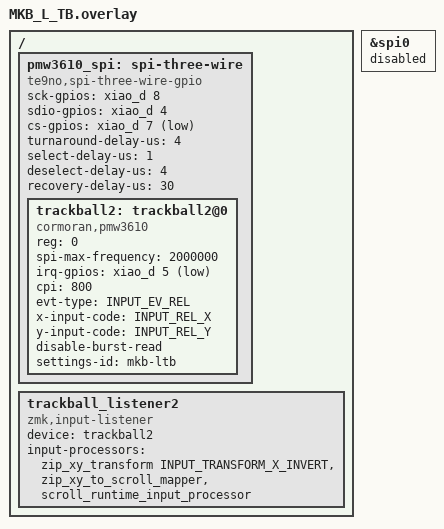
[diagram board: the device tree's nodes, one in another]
/ {
	pmw3610_spi: spi-three-wire {
		compatible = "te9no,spi-three-wire-gpio";
		status = "okay";
		#address-cells = <1>;
		#size-cells = <0>;

		/* MKB left TB wiring: SCK=P1.13 (D8), shared SDIO=P0.04 (D4). */
		sck-gpios = <&xiao_d 8 GPIO_ACTIVE_HIGH>;
		sdio-gpios = <&xiao_d 4 GPIO_ACTIVE_HIGH>;
		cs-gpios = <&xiao_d 7 GPIO_ACTIVE_LOW>;

		turnaround-delay-us = <4>;
		select-delay-us = <1>;
		deselect-delay-us = <4>;
		recovery-delay-us = <30>;

		trackball2: trackball2@0 {
			status = "okay";
			compatible = "cormoran,pmw3610";
			reg = <0>;
			spi-max-frequency = <2000000>;
			irq-gpios = <&xiao_d 5 (GPIO_ACTIVE_LOW | GPIO_PULL_UP)>;
			cpi = <800>;
			evt-type = <INPUT_EV_REL>;
			x-input-code = <INPUT_REL_X>;
			y-input-code = <INPUT_REL_Y>;
			disable-burst-read;
			settings-id = "mkb-ltb";
		};
	};

	trackball_listener2: trackball_listener2 {
        compatible = "zmk,input-listener";
        device = <&trackball2>;
        status = "okay";
        input-processors = <&zip_xy_transform INPUT_TRANSFORM_X_INVERT>,
                           <&zip_xy_to_scroll_mapper &scroll_runtime_input_processor>;
	};
};

&spi0 {
	status = "disabled";
};
